# MSP430FR2355 register map
Vendor: msp430gen; File version: v0.4.0-28-gb0087ce-dirty
Registers are 16-bit, read-write, reset 0x0 unless marked. A register's access mark holds for its fields unless they carry their own. Offsets are from the block's base; [hi:lo] are bit positions; {n}, {i} and the like mark numbered series.

## CS
Base 0x00000180
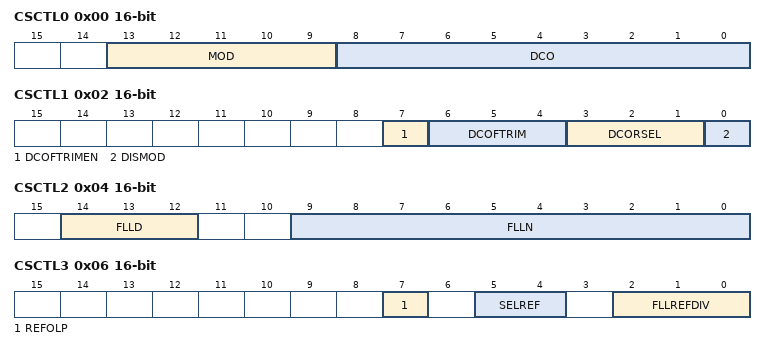
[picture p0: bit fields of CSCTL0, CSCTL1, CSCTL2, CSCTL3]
0x00 CSCTL0 — Clock System Control 0
  [13:9] MOD — Modulation bit counter. These bits select the modulation pattern. All MOD bits are modified automatically during FLL operation. The DCO register value is incremented when the modulation bit counter rolls over from 31 to 0. If the modulation bit counter decrements from 0 to the maximum count, the DCO register value is also decreased.
  [8:0] DCO — DCO tap selection. These bits select the DCO tap and are modified automatically during FLL operation.
0x02 CSCTL1 — Clock System Control 1
  [7] DCOFTRIMEN — DCO Frequency Trim Enable. When this bit is set, DCOFTRIM value is selected to set DCO frequency. Otherwise, DCOFTRIM value is bypassed and DCO applies default settings in manufacture.
    0=Disable frequency trim; 1=Enable frequency trim
  [6:4] DCOFTRIM — DCO frequency trim. These bits trims the DCO frequency. By default, it is chipspecific trimmed. These bits can also be trimmed by user code.
  [3:1] DCORSEL — DCO Range Select
    0=RANGE_1MHZ (1 MHz); 1=RANGE_2MHZ (2 MHz); 2=RANGE_4MHZ (4 MHz); 3=RANGE_8MHZ (8 MHz); 4=RANGE_12MHZ (12 MHz); 5=RANGE_16MHZ (16 MHz); 6=RANGE_20MHZ (20 MHz); 7=RANGE_24MHZ (24 MHz)
  [0] DISMOD — Modulation. This bit enables/disables the modulation.
    0=Modulation enabled; 1=Modulation disabled
0x04 CSCTL2 — Clock System Control 2
  [14:12] FLLD — FLL loop divider. These bits divide f(DCOCLK) in the FLL feedback loop. This results in an additional multiplier for the multiplier bits. See also multiplier bits.
    0=fDCOCLK / 1; 1=fDCOCLK / 2; 2=fDCOCLK / 4; 3=fDCOCLK / 8; 4=fDCOCLK / 16; 5=fDCOCLK / 32; 6=fDCOCLK / 40(Only avaliable in 24MHz clock system); 7=fDCOCLK / 48(Only avaliable in 24MHz clock system)
  [9:0] FLLN — Multiplier bits. These bits set the multiplier value N of the DCO. N must be greater than 0. Writing zero to FLLN causes N to be set to 1.
0x06 CSCTL3 — Clock System Control 3
  [7] REFOLP — REFO Low Power Enable. This bit turns on REFO low-power mode. During switch, the low-power mode will be invalid until REFOREADY is set.
    0=REFO Low Power Disabled (High Power Mode); 1=REFO Low Power Enabled
  [5:4] SELREF — FLL reference select. These bits select the FLL reference clock source.
    0=XT1CLK; 1=REFOCLK; 2=served for future use; 3=served for future use
  [2:0] FLLREFDIV — FLL reference divider. These bits define the divide factor for f(FLLREFCLK). If XT1 supports high frequency input higher than 32 kHz, the divided frequency is used as the FLL reference frequency. If XT1 only supports 32-kHz clock, FLLREFDIV is always read and written as zero, 000b = fFLLREFCLK / 1
    0=/1 (fFLLREFCLK / 1); 1=/32 (fFLLREFCLK / 32); 2=/64 (fFLLREFCLK / 64); 3=/128 (fFLLREFCLK / 128); 4=/256 (fFLLREFCLK / 256); 5=/512 (fFLLREFCLK / 512); 6=/640 (fFLLREFCLK / 640); 7=/768 (fFLLREFCLK / 768)
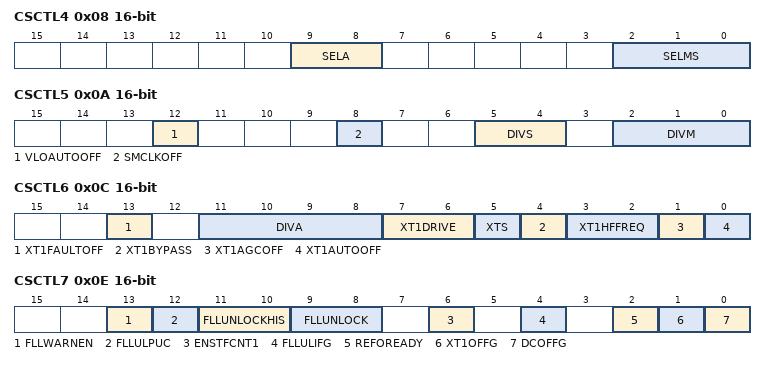
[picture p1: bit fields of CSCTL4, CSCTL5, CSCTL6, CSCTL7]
0x08 CSCTL4 — Clock System Control 4
  [9:8] SELA — Selects the ACLK source
    0=XT1CLK (XT1CLK with divider (must be no more than 40 kHz)); 1=REFOCLK (REFO (internal 32-kHz clock source)); 2=VLOCLK (VLO (internal 10-kHz clock source))
  [2:0] SELMS — Selects the MCLK and SMCLK source
    0=DCOCLKDIV; 1=REFOCLK; 2=XT1CLK; 3=VLOCLK; {v}=Reserved for future use (v=4..7)
0x0A CSCTL5 — Clock System Control 5
  [12] VLOAUTOOFF — VLO automatic off enable. This bit turns off VLO, if VLO is not used.
    0=VLO always on; 1=VLO automatically turned off if not used(default)
  [8] SMCLKOFF — SMCLK off. This bit turns off SMCLK clock
    0=SMCLK on; 1=SMCLK off
  [5:4] DIVS — SMCLK source divider. SMCLK directly derives from MCLK. SMCLK frequency is the combination of DIVM and DIVS out of selected clock source.
    0=1; 1=2; 2=4; 3=8
  [2:0] DIVM — MCLK source divider
    0=1; 1=2; 2=4; 3=8; 4=16; 5=32; 6=64; 7=128
0x0C CSCTL6 — Clock System Control 6
  [13] XT1FAULTOFF — The XT1 oscillator fault detection off
    0=Enabling XT1 fault to switch ACLK to REFO; 1=Disabling XT1 fault to switch ACLK to REFO
  [11:8] DIVA — ACLK source divider.
    0=1; 1=16; 2=32; 3=64; 4=128; 5=256; 6=384; 7=512; 8=/768(Only available in 24MHz clock system, 24 MHz preference); 9=/1024(Only available in 24MHz clock system, 24 MHz preference); 10=/108(Only available in 24MHz clock system, 24 MHz preference); 11=338(Only available in 24MHz clock system, 24 MHz preference); 12=414(Only available in 24MHz clock system, 24 MHz preference); 13=640(Only available in 24MHz clock system, 24 MHz preference)
  [7:6] XT1DRIVE — The XT1 oscillator current can be adjusted to its drive needs. Initially, it starts with the highest supply current for reliable and quick startup. If needed, user software can reduce the drive strength. The configuration of these bits is retained during LPM3.5 until LOCKLPM5 is cleared, but not the register bits itself; therefore, reconfiguration after wake-up from LPM3.5 before clearing LOCKLPM5 is required.
    0=Lowest drive strength and current consumption; 1=Lower drive strength and current consumption; 2=Higher drive strength and current consumption; 3=Highest drive strength and current consumption
  [5] XTS — XT1 mode select
    0=Low-frequency mode; 1=High-frequency mode
  [4] XT1BYPASS — XT1 bypass select
    0=XT1 source internally; 1=XT1 sources externally from pin
  [3:2] XT1HFFREQ — The XT1 High-frequency selection. These bits must be set to appropriate frequency for crystal or bypass modes of operation.
    0=1 to 4 MHz; 1=4 MHz to 6 MHz; 2=6 MHz to 16 MHz; 3=16 MHz to 24 MHz
  [1] XT1AGCOFF — Automatic Gain Control (AGC) disable.
    0=AGC on; 1=AGC off
  [0] XT1AUTOOFF — XT1 automatic off enable. This bit allows XT1 turned turns off when it is not used
    0=XT1 is on if XT1 is selected by the port selection and XT1 is not in bypass mode of operation; 1=XT1 is off if it is not used as a source for ACLK, MCLK, or SMCLK or is not used as a reference source required for FLL operation
0x0E CSCTL7 — Clock System Control Register 7
  [13] FLLWARNEN — Warning enable. If this bit is set, an interrupt is generated based on the FLLUNLOCKHIS bits. If FLLUNLOCKHIS is not equal to 00, an OFIFG is generated.
    0=DISABLED (FLLUNLOCKHIS status cannot set OFIFG.); 1=ENABLED (FLLUNLOCKHIS status can set OFIFG.)
  [12] FLLULPUC — FLL unlock PUC enable. If the FLLULPUC bit is set, a reset (PUC) is triggered if FLLULIFG is set. FLLULIFG indicates when FLLUNLOCK bits equal 10 (too fast). FLLULPUC is automatically cleared upon servicing the event. If FLLULPUC is cleared (0), no PUC can be triggered by FLLULIFG.
  [11:10] FLLUNLOCKHIS — Unlock history bits. These bits indicate the FLL unlock condition history. As soon as any unlock condition happens, the respective bits are set and remain set until cleared by software by writing 0 to it or by a POR.
    0=LOCKED (FLL is locked. No unlock situation has been detected since the last reset of these bits.); 1=TOO_SLOW (DCOCLK has been too slow since the bits were cleared.); 2=TOO_FAST (DCOCLK has been too fast since the bits were cleared.); 3=TOO_SLOW_AND_FAST (DCOCLK has been both too fast and too slow since the bits were cleared.)
  [9:8] FLLUNLOCK — Unlock. These bits indicate the current FLL unlock condition. These bits are both set as long as the DCOFFG flag is set.
    0=LOCKED (FLL is locked. No unlock condition currently active.); 1=TOO_SLOW (DCOCLK is currently too slow.); 2=TOO_FAST (DCOCLK is currently too fast.); 3=OUT_OF_RANGE (DCOERROR. DCO out of range.)
  [6] ENSTFCNT1 — Enable start counter for XT1.
    0=Startup fault counter disabled. Counter is cleared..; 1=Startup fault counter enabled
  [4] FLLULIFG — FLL unlock interrupt flag. This flag is set when FLLUNLOCK bits equal 10b (DCO too fast). If FLLULPUC is also set, a PUC is triggered when FLLUIFG is set.
    0=FLLUNLOCK bits not equal to 10b; 1=FLLUNLOCK bits equal to 10b
  [2] REFOREADY ro — REFO ready flag. This bit reflects the REFO readiness whent REFO is good for operation (such as FLL reference)
    0=REFO unstable; 1=REFO ready to go
  [1] XT1OFFG — T1 oscillator fault flag. If this bit is set, the OFIFG flag is also set. XT1OFFG is set if a XT1 fault condition exists. XT1OFFG can be cleared by software. If the XT1 fault condition still remains, XT1OFFG is set.
    0=No fault condition occurred after the last reset; 1=XT1 fault. An XT1 fault occurred after the last reset.
  [0] DCOFFG — DCO fault flag. If this bit is set, the OFIFG flag is also set. The DCOFFG bit is set if DCO = {0} or DCO = {511}. DCOFFG can be cleared by software. If the DCO fault condition still remains, DCOFFG is set. As long as DCOFFG is set, FLLUNLOCK shows the DCOERROR condition.
    0=No fault condition occurred after the last reset; 1=DCO fault. A DCO fault occurred after the last reset.
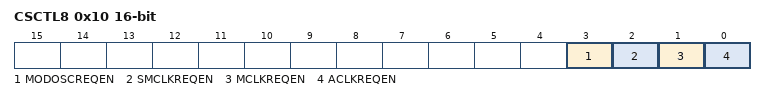
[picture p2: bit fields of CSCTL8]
0x10 CSCTL8 — Clock System Control Register 8
  [3] MODOSCREQEN — MODOSC clock request enable. Setting this enables conditional module requests for MODOSC.
    0=MODOSC conditional requests are disabled; 1=MODOSC conditional requests are enabled
  [2] SMCLKREQEN — SMCLK clock request enable. Setting this enables conditional module requests for SMCLK
    0=SMCLK conditional requests are disabled; 1=SMCLK conditional requests are enabled
  [1] MCLKREQEN — MCLK clock request enable. Setting this enables conditional module requests for MCLK
    0=MCLK conditional requests are disabled; 1=MCLK conditional requests are enabled
  [0] ACLKREQEN — ACLK clock request enable. Setting this enables conditional module requests for ACLK
    0=ACLK conditional requests are disabled; 1=ACLK conditional requests are enabled
